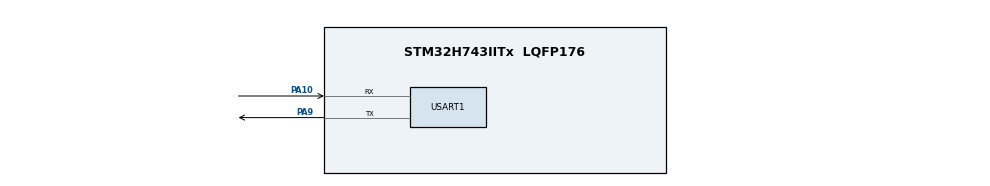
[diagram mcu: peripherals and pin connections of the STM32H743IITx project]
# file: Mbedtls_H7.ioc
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CORTEX_M7.AccessPermission-Cortex_Memory_Protection_Unit_Region0_Settings=MPU_REGION_FULL_ACCESS
CORTEX_M7.AccessPermission-Cortex_Memory_Protection_Unit_Region1_Settings=MPU_REGION_FULL_ACCESS
CORTEX_M7.BaseAddress-Cortex_Memory_Protection_Unit_Region0_Settings=0x24000000
CORTEX_M7.BaseAddress-Cortex_Memory_Protection_Unit_Region1_Settings=0x30000000
CORTEX_M7.CPU_DCache=Disabled
CORTEX_M7.CPU_ICache=Disabled
CORTEX_M7.Enable-Cortex_Memory_Protection_Unit_Region0_Settings=MPU_REGION_ENABLE
CORTEX_M7.Enable-Cortex_Memory_Protection_Unit_Region1_Settings=MPU_REGION_ENABLE
CORTEX_M7.IsBufferable-Cortex_Memory_Protection_Unit_Region0_Settings=MPU_ACCESS_BUFFERABLE
CORTEX_M7.IsBufferable-Cortex_Memory_Protection_Unit_Region1_Settings=MPU_ACCESS_BUFFERABLE
CORTEX_M7.IsCacheable-Cortex_Memory_Protection_Unit_Region0_Settings=MPU_ACCESS_CACHEABLE
CORTEX_M7.IsShareable-Cortex_Memory_Protection_Unit_Region1_Settings=MPU_ACCESS_SHAREABLE
CORTEX_M7.MPU_Control=__NULL
CORTEX_M7.Size-Cortex_Memory_Protection_Unit_Region0_Settings=MPU_REGION_SIZE_512KB
CORTEX_M7.Size-Cortex_Memory_Protection_Unit_Region1_Settings=MPU_REGION_SIZE_256KB
CORTEX_M7.TypeExtField-Cortex_Memory_Protection_Unit_Region0_Settings=MPU_TEX_LEVEL1
Dma.Request0=USART1_RX
Dma.Request1=USART1_TX
Dma.USART1_RX.0.Direction=DMA_PERIPH_TO_MEMORY
Dma.USART1_RX.0.EventEnable=DISABLE
Dma.USART1_RX.0.FIFOMode=DMA_FIFOMODE_DISABLE
Dma.USART1_RX.0.Instance=DMA1_Stream0
Dma.USART1_RX.0.MemDataAlignment=DMA_MDATAALIGN_BYTE
Dma.USART1_RX.0.MemInc=DMA_MINC_ENABLE
Dma.USART1_RX.0.Mode=DMA_NORMAL
Dma.USART1_RX.0.PeriphDataAlignment=DMA_PDATAALIGN_BYTE
Dma.USART1_RX.0.PeriphInc=DMA_PINC_DISABLE
Dma.USART1_RX.0.Polarity=HAL_DMAMUX_REQ_GEN_RISING
Dma.USART1_RX.0.Priority=DMA_PRIORITY_LOW
Dma.USART1_RX.0.RequestNumber=1
Dma.USART1_RX.0.SignalID=NONE
Dma.USART1_RX.0.SyncEnable=DISABLE
Dma.USART1_RX.0.SyncPolarity=HAL_DMAMUX_SYNC_NO_EVENT
Dma.USART1_RX.0.SyncRequestNumber=1
Dma.USART1_RX.0.SyncSignalID=NONE
Dma.USART1_TX.1.Direction=DMA_MEMORY_TO_PERIPH
Dma.USART1_TX.1.EventEnable=DISABLE
Dma.USART1_TX.1.FIFOMode=DMA_FIFOMODE_DISABLE
Dma.USART1_TX.1.Instance=DMA1_Stream1
Dma.USART1_TX.1.MemDataAlignment=DMA_MDATAALIGN_BYTE
Dma.USART1_TX.1.MemInc=DMA_MINC_ENABLE
Dma.USART1_TX.1.Mode=DMA_NORMAL
Dma.USART1_TX.1.PeriphDataAlignment=DMA_PDATAALIGN_BYTE
Dma.USART1_TX.1.PeriphInc=DMA_PINC_DISABLE
Dma.USART1_TX.1.Polarity=HAL_DMAMUX_REQ_GEN_RISING
Dma.USART1_TX.1.Priority=DMA_PRIORITY_LOW
Dma.USART1_TX.1.RequestNumber=1
Dma.USART1_TX.1.SignalID=NONE
Dma.USART1_TX.1.SyncEnable=DISABLE
Dma.USART1_TX.1.SyncPolarity=HAL_DMAMUX_SYNC_NO_EVENT
Dma.USART1_TX.1.SyncRequestNumber=1
Dma.USART1_TX.1.SyncSignalID=NONE
MBEDTLS.MBEDTLS_HAVE_TIME=0
MBEDTLS.MBEDTLS_HAVE_TIME_DATE=0
MBEDTLS.MBEDTLS_SSL_CLI_C=1
Mcu.Family=STM32H7
Mcu.Name=STM32H743IITx
Mcu.Package=LQFP176
NVIC.DMA1_Stream0_IRQn=true\:0\:0\:false\:false\:true\:false\:true
NVIC.DMA1_Stream1_IRQn=true\:0\:0\:false\:false\:true\:false\:true
NVIC.PriorityGroup=NVIC_PRIORITYGROUP_4
NVIC.USART1_IRQn=true\:0\:0\:false\:false\:true\:true\:true
PA10.GPIO_Speed=GPIO_SPEED_FREQ_VERY_HIGH
PA10.Mode=Asynchronous
PA10.Signal=USART1_RX
PA9.GPIO_Speed=GPIO_SPEED_FREQ_VERY_HIGH
PA9.Mode=Asynchronous
PA9.Signal=USART1_TX
PC14-OSC32_IN\ (OSC32_IN).Mode=LSE-External-Oscillator
PC14-OSC32_IN\ (OSC32_IN).Signal=RCC_OSC32_IN
PC15-OSC32_OUT\ (OSC32_OUT).Mode=LSE-External-Oscillator
PC15-OSC32_OUT\ (OSC32_OUT).Signal=RCC_OSC32_OUT
PH0-OSC_IN\ (PH0).Mode=HSE-External-Oscillator
PH0-OSC_IN\ (PH0).Signal=RCC_OSC_IN
PH1-OSC_OUT\ (PH1).Mode=HSE-External-Oscillator
PH1-OSC_OUT\ (PH1).Signal=RCC_OSC_OUT
ProjectManager.HeapSize=0x2000
ProjectManager.StackSize=0x4000
ProjectManager.TargetToolchain=MDK-ARM V5.32
RCC.ADCFreq_Value=50390625
RCC.APB1Freq_Value=100000000
RCC.APB2Freq_Value=100000000
RCC.APB3Freq_Value=100000000
RCC.APB4Freq_Value=100000000
RCC.CortexFreq_Value=400000000
RCC.D1PPRE=RCC_APB3_DIV2
RCC.D2PPRE1=RCC_APB1_DIV2
RCC.D2PPRE2=RCC_APB2_DIV2
RCC.D3PPRE=RCC_APB4_DIV2
RCC.DIVM1=5
RCC.DIVN1=160
RCC.HCLKFreq_Value=200000000
RCC.HPRE=RCC_HCLK_DIV2
RCC.PLLSourceVirtual=RCC_PLLSOURCE_HSE
RCC.SYSCLKFreq_VALUE=400000000
RCC.SYSCLKSource=RCC_SYSCLKSOURCE_PLLCLK
RCC.USBFreq_Value=400000000
TIM12.Prescaler=199
USART1.VirtualMode-Asynchronous=VM_ASYNC
VP_MBEDTLS_VS_MBEDTLS.Mode=Enabled
VP_RNG_VS_RNG.Mode=RNG_Activate
VP_TIM12_VS_ClockSourceINT.Mode=Internal
board=custom

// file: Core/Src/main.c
/* USER CODE BEGIN Header */
/**
  ******************************************************************************
  * @file           : main.c
  * @brief          : Main program body
  ******************************************************************************
  * @attention
  *
  * Copyright (c) 2022 STMicroelectronics.
  * All rights reserved.
  *
  * This software is licensed under terms that can be found in the LICENSE file
  * in the root directory of this software component.
  * If no LICENSE file comes with this software, it is provided AS-IS.
  *
  ******************************************************************************
  */
/* USER CODE END Header */
#include "main.h"
#include "mbedtls.h"

/* USER CODE BEGIN Includes */
#include "ram_mgmt.h"
#include "delay.h"
#include "uart.h"

#include "mbedtls/entropy.h"
#include "mbedtls/ctr_drbg.h"
#include "mbedtls/rsa.h"
#include "mbedtls/md.h"

#include <string.h>
#include <stdio.h>
/* USER CODE END Includes */

/* USER CODE BEGIN PM */
#define RCV_LEN		0
#define RCV_DATA	1

/* USER CODE END PM */

RNG_HandleTypeDef hrng;

TIM_HandleTypeDef htim12;

UART_HandleTypeDef huart1;
DMA_HandleTypeDef hdma_usart1_rx;
DMA_HandleTypeDef hdma_usart1_tx;

/* USER CODE BEGIN PV */
UART_Sta uart1_sta;

unsigned char rcv_flag = RCV_LEN;
unsigned char* rcv_data = NULL;
unsigned char* pub_key = NULL;
unsigned char* sig = NULL;
unsigned char* msg = NULL;
int rcv_pub_key_len = 0;
int pub_key_len = 0;
int sig_len = 0;
int msg_len = 0;
int data_pkg_len = 0;

int res;
unsigned char hash[32];
/* USER CODE END PV */

void SystemClock_Config(void);
static void MX_GPIO_Init(void);
static void MX_DMA_Init(void);
static void MX_RNG_Init(void);
static void MX_USART1_UART_Init(void);
static void MX_TIM12_Init(void);

/* USER CODE BEGIN 0 */

int Parse_DataLen(unsigned char *data) {

	rcv_pub_key_len = data[1] << 24 | data[2] << 16 | data[3] << 8 | data[4];
	if (rcv_pub_key_len > 0) {
		pub_key_len = rcv_pub_key_len;
	}
	sig_len = (data[5] << 24) + (data[6] << 16) + (data[7] << 8) + data[8];
	msg_len = (data[9] << 24) + (data[10] << 16) + (data[11] << 8) + data[12];

	if (rcv_pub_key_len >= 0 && sig_len >= 0 && msg_len >= 0) {
		return (pub_key_len + msg_len + sig_len + 1);
	} else {
		return -1;
	}
}

void Parse_Key_Msg(unsigned char *data) {
	unsigned char *p = data;
	p++;
	if (rcv_pub_key_len != 0) {
		my_free(SRAMIN, pub_key);
		pub_key = my_malloc(SRAMIN, pub_key_len + 1);
		my_memclear((char*)pub_key, pub_key_len + 1);
		my_memcpy(pub_key, p, pub_key_len);
	}
	p += rcv_pub_key_len;
	sig = p;
	p += sig_len;
	msg = p;
}

/* USER CODE END 0 */

int main(void)
{

  /* MCU Configuration--------------------------------------------------------*/

  /* Reset of all peripherals, Initializes the Flash interface and the Systick. */
  HAL_Init();

  /* Configure the system clock */
  SystemClock_Config();

  /* Initialize all configured peripherals */
  MX_GPIO_Init();
  MX_DMA_Init();
  MX_RNG_Init();
  MX_USART1_UART_Init();
  MX_MBEDTLS_Init();
  MX_TIM12_Init();
  /* USER CODE BEGIN 2 */
  my_mem_init(SRAMIN);
  my_mem_init(SRAM12);

  UART_StaInit(&uart1_sta, &huart1, &hdma_usart1_rx);

  /* USER CODE END 2 */

  /* Infinite loop */
  while (1)
  {

    /* USER CODE BEGIN 3 */

	if (rcv_flag == RCV_LEN) {
		rcv_data = (unsigned char*)UART_WaitOnRevNumData(&uart1_sta, 13, 20);

		if (rcv_data != NULL && rcv_data[0] == 'L') {

			data_pkg_len = Parse_DataLen(rcv_data);
			my_free(SRAM12, rcv_data);
			rcv_data = NULL;

			if (data_pkg_len > 0) {
				rcv_flag = RCV_DATA;
				UART_SendNumData(&uart1_sta, "L", 1, 0);
			} else {
				// illegal data package length
			}
		} else {
			// no package received or wrong package
		}

	} else {
		rcv_data = (unsigned char*)UART_WaitOnRevNumData(&uart1_sta, data_pkg_len, 20);

		if (rcv_data != NULL && rcv_data[0] == 'D') {
			res = 0;
			Parse_Key_Msg(rcv_data);

			mbedtls_pk_context pk;
			mbedtls_pk_init(&pk);

			// Import the public key
			res += mbedtls_pk_parse_public_key(&pk, pub_key, pub_key_len + 1);
			// SHA 256
			res += mbedtls_md(mbedtls_md_info_from_type(MBEDTLS_MD_SHA256), msg, msg_len, hash);
			if (res == 0) {
				res += mbedtls_pk_verify(&pk, MBEDTLS_MD_SHA256, hash, 32, sig, sig_len);
			} else {
				UART_SendNumData(&uart1_sta, "IN_E", 5, 0);
			}

			mbedtls_pk_free(&pk);
			my_free(SRAM12, rcv_data);
			rcv_data = NULL;
			rcv_flag = RCV_LEN;

			if (res == 0) {
				UART_SendNumData(&uart1_sta, "PASS", 5, 0);
			} else {
				UART_SendNumData(&uart1_sta, "ERR\0", 5, 0);
			}
		} else {
			// no package received or wrong package
		}
	}
  }
  /* USER CODE END 3 */
}

void SystemClock_Config(void)
{
  RCC_OscInitTypeDef RCC_OscInitStruct = {0};
  RCC_ClkInitTypeDef RCC_ClkInitStruct = {0};

  /** Supply configuration update enable
  */
  HAL_PWREx_ConfigSupply(PWR_LDO_SUPPLY);
  /** Configure the main internal regulator output voltage
  */
  __HAL_PWR_VOLTAGESCALING_CONFIG(PWR_REGULATOR_VOLTAGE_SCALE1);

  while(!__HAL_PWR_GET_FLAG(PWR_FLAG_VOSRDY)) {}
  /** Initializes the RCC Oscillators according to the specified parameters
  * in the RCC_OscInitTypeDef structure.
  */
  RCC_OscInitStruct.OscillatorType = RCC_OSCILLATORTYPE_HSI48|RCC_OSCILLATORTYPE_HSE;
  RCC_OscInitStruct.HSEState = RCC_HSE_ON;
  RCC_OscInitStruct.HSI48State = RCC_HSI48_ON;
  RCC_OscInitStruct.PLL.PLLState = RCC_PLL_ON;
  RCC_OscInitStruct.PLL.PLLSource = RCC_PLLSOURCE_HSE;
  RCC_OscInitStruct.PLL.PLLM = 5;
  RCC_OscInitStruct.PLL.PLLN = 160;
  RCC_OscInitStruct.PLL.PLLP = 2;
  RCC_OscInitStruct.PLL.PLLQ = 2;
  RCC_OscInitStruct.PLL.PLLR = 2;
  RCC_OscInitStruct.PLL.PLLRGE = RCC_PLL1VCIRANGE_2;
  RCC_OscInitStruct.PLL.PLLVCOSEL = RCC_PLL1VCOWIDE;
  RCC_OscInitStruct.PLL.PLLFRACN = 0;
  if (HAL_RCC_OscConfig(&RCC_OscInitStruct) != HAL_OK)
  {
    Error_Handler();
  }
  /** Initializes the CPU, AHB and APB buses clocks
  */
  RCC_ClkInitStruct.ClockType = RCC_CLOCKTYPE_HCLK|RCC_CLOCKTYPE_SYSCLK
                              |RCC_CLOCKTYPE_PCLK1|RCC_CLOCKTYPE_PCLK2
                              |RCC_CLOCKTYPE_D3PCLK1|RCC_CLOCKTYPE_D1PCLK1;
  RCC_ClkInitStruct.SYSCLKSource = RCC_SYSCLKSOURCE_PLLCLK;
  RCC_ClkInitStruct.SYSCLKDivider = RCC_SYSCLK_DIV1;
  RCC_ClkInitStruct.AHBCLKDivider = RCC_HCLK_DIV2;
  RCC_ClkInitStruct.APB3CLKDivider = RCC_APB3_DIV2;
  RCC_ClkInitStruct.APB1CLKDivider = RCC_APB1_DIV2;
  RCC_ClkInitStruct.APB2CLKDivider = RCC_APB2_DIV2;
  RCC_ClkInitStruct.APB4CLKDivider = RCC_APB4_DIV2;

  if (HAL_RCC_ClockConfig(&RCC_ClkInitStruct, FLASH_LATENCY_2) != HAL_OK)
  {
    Error_Handler();
  }
}

static void MX_RNG_Init(void)
{

  hrng.Instance = RNG;
  hrng.Init.ClockErrorDetection = RNG_CED_ENABLE;
  if (HAL_RNG_Init(&hrng) != HAL_OK)
  {
    Error_Handler();
  }

}

static void MX_TIM12_Init(void)
{

  TIM_ClockConfigTypeDef sClockSourceConfig = {0};

  htim12.Instance = TIM12;
  htim12.Init.Prescaler = 199;
  htim12.Init.CounterMode = TIM_COUNTERMODE_UP;
  htim12.Init.Period = 65535;
  htim12.Init.ClockDivision = TIM_CLOCKDIVISION_DIV1;
  htim12.Init.AutoReloadPreload = TIM_AUTORELOAD_PRELOAD_DISABLE;
  if (HAL_TIM_Base_Init(&htim12) != HAL_OK)
  {
    Error_Handler();
  }
  sClockSourceConfig.ClockSource = TIM_CLOCKSOURCE_INTERNAL;
  if (HAL_TIM_ConfigClockSource(&htim12, &sClockSourceConfig) != HAL_OK)
  {
    Error_Handler();
  }

}

static void MX_USART1_UART_Init(void)
{

  huart1.Instance = USART1;
  huart1.Init.BaudRate = 115200;
  huart1.Init.WordLength = UART_WORDLENGTH_8B;
  huart1.Init.StopBits = UART_STOPBITS_1;
  huart1.Init.Parity = UART_PARITY_NONE;
  huart1.Init.Mode = UART_MODE_TX_RX;
  huart1.Init.HwFlowCtl = UART_HWCONTROL_NONE;
  huart1.Init.OverSampling = UART_OVERSAMPLING_16;
  huart1.Init.OneBitSampling = UART_ONE_BIT_SAMPLE_DISABLE;
  huart1.Init.ClockPrescaler = UART_PRESCALER_DIV1;
  huart1.AdvancedInit.AdvFeatureInit = UART_ADVFEATURE_NO_INIT;
  if (HAL_UART_Init(&huart1) != HAL_OK)
  {
    Error_Handler();
  }
  if (HAL_UARTEx_SetTxFifoThreshold(&huart1, UART_TXFIFO_THRESHOLD_1_8) != HAL_OK)
  {
    Error_Handler();
  }
  if (HAL_UARTEx_SetRxFifoThreshold(&huart1, UART_RXFIFO_THRESHOLD_1_8) != HAL_OK)
  {
    Error_Handler();
  }
  if (HAL_UARTEx_DisableFifoMode(&huart1) != HAL_OK)
  {
    Error_Handler();
  }

}

static void MX_DMA_Init(void)
{

  /* DMA controller clock enable */
  __HAL_RCC_DMA1_CLK_ENABLE();

  /* DMA interrupt init */
  /* DMA1_Stream0_IRQn interrupt configuration */
  HAL_NVIC_SetPriority(DMA1_Stream0_IRQn, 0, 0);
  HAL_NVIC_EnableIRQ(DMA1_Stream0_IRQn);
  /* DMA1_Stream1_IRQn interrupt configuration */
  HAL_NVIC_SetPriority(DMA1_Stream1_IRQn, 0, 0);
  HAL_NVIC_EnableIRQ(DMA1_Stream1_IRQn);

}

static void MX_GPIO_Init(void)
{

  /* GPIO Ports Clock Enable */
  __HAL_RCC_GPIOC_CLK_ENABLE();
  __HAL_RCC_GPIOH_CLK_ENABLE();
  __HAL_RCC_GPIOA_CLK_ENABLE();

}

void Error_Handler(void)
{
  __disable_irq();
  while (1)
  {
  }
}
